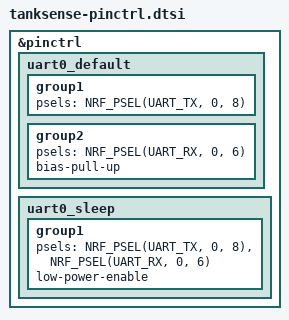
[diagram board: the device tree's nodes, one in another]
&pinctrl {
	/* EG800Q via TXS0108E. Direction CONFIRMED in KiCad:
	 * UART_EG800Q_RXD (P0.08) -> MAIN_RXD (17)  = nRF TX
	 * UART_EG800Q_TXD (P0.06) <- MAIN_TXD (18)  = nRF RX
	 * RTS/CTS (P0.27/P1.08) not assigned yet - flow control off for first test */
	uart0_default: uart0_default {
		group1 {
			psels = <NRF_PSEL(UART_TX, 0, 8)>;
		};
		group2 {
			psels = <NRF_PSEL(UART_RX, 0, 6)>;
			bias-pull-up;
		};
	};

	uart0_sleep: uart0_sleep {
		group1 {
			psels = <NRF_PSEL(UART_TX, 0, 8)>,
				<NRF_PSEL(UART_RX, 0, 6)>;
			low-power-enable;
		};
	};
};
